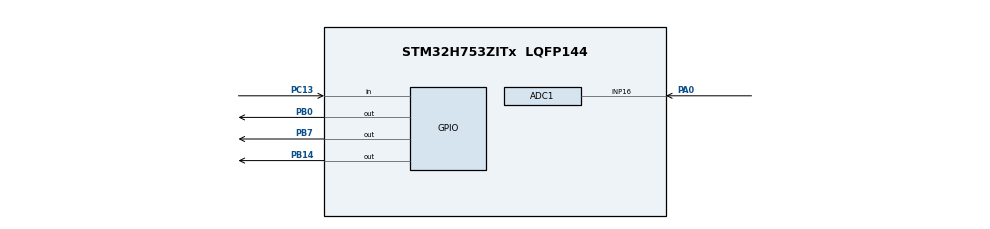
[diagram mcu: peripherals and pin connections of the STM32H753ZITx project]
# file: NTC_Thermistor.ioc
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ADC1.Channel-0\#ChannelRegularConversion=ADC_CHANNEL_16
ADC1.NbrOfConversionFlag=1
ADC1.OffsetNumber-0\#ChannelRegularConversion=ADC_OFFSET_NONE
ADC1.OffsetSignedSaturation-0\#ChannelRegularConversion=DISABLE
ADC1.Rank-0\#ChannelRegularConversion=1
ADC1.SamplingTime-0\#ChannelRegularConversion=ADC_SAMPLETIME_810CYCLES_5
ADC1.master=1
CORTEX_M7.CPU_DCache=Disabled
CORTEX_M7.CPU_ICache=Disabled
CORTEX_M7.MPU_Control=__NULL
CORTEX_M7.default_mode_Activation=1
Mcu.Family=STM32H7
Mcu.Name=STM32H753ZITx
Mcu.Package=LQFP144
NUCLEO-H753ZI.BUTTON=1
NUCLEO-H753ZI.LD1=true
NUCLEO-H753ZI.LD2=true
NUCLEO-H753ZI.LD3=true
NUCLEO-H753ZI.VCP=true
NVIC.EXTI15_10_IRQn=true\:0\:0\:false\:false\:true\:false\:true\:true
NVIC.PriorityGroup=NVIC_PRIORITYGROUP_4
PA0.Mode=IN16-Single-Ended
PA0.Signal=ADC1_INP16
PB0.Signal=GPIO_Output
PB14.Signal=GPIO_Output
PB7.Signal=GPIO_Output
PC13.Signal=GPIO_Input
PC14-OSC32_IN\ (OSC32_IN).Signal=RCC_OSC32_IN
PC15-OSC32_OUT\ (OSC32_OUT).Signal=RCC_OSC32_OUT
PD8.Signal=USART3_TX
PD9.Signal=USART3_RX
PH0-OSC_IN\ (PH0).Signal=RCC_OSC_IN
PH1-OSC_OUT\ (PH1).Signal=RCC_OSC_OUT
ProjectManager.HeapSize=0x200
ProjectManager.StackSize=0x400
ProjectManager.TargetToolchain=STM32CubeIDE
RCC.ADCFreq_Value=129000000
RCC.APB1Freq_Value=64000000
RCC.APB2Freq_Value=64000000
RCC.APB3Freq_Value=64000000
RCC.APB4Freq_Value=64000000
RCC.CortexFreq_Value=64000000
RCC.DIVM1=1
RCC.DIVN1=24
RCC.DIVQ1=4
RCC.HCLKFreq_Value=64000000
RCC.HSE_VALUE=8000000
RCC.PLLFRACN=0
RCC.PWR_Regulator_Voltage_Scale=PWR_REGULATOR_VOLTAGE_SCALE2
RCC.SYSCLKFreq_VALUE=64000000
RCC.USBFreq_Value=384000000
VP_MEMORYMAP_VS_MEMORYMAP.Mode=CurAppReg
VP_NUCLEO-H753ZI_VS_BSP_COMMON.Mode=COMMON
board=NUCLEO-H753ZI

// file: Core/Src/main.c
/* USER CODE BEGIN Header */
/**
  ******************************************************************************
  * @file           : main.c
  * @brief          : Main program body
  ******************************************************************************
  * @attention
  *
  * Copyright (c) 2025 STMicroelectronics.
  * All rights reserved.
  *
  * This software is licensed under terms that can be found in the LICENSE file
  * in the root directory of this software component.
  * If no LICENSE file comes with this software, it is provided AS-IS.
  *
  ******************************************************************************
  */
/* USER CODE END Header */
#include "main.h"

/* USER CODE BEGIN Includes */
#include "thermistor.h"
#include <stdio.h>
/* USER CODE END Includes */

COM_InitTypeDef BspCOMInit;
ADC_HandleTypeDef hadc1;

void SystemClock_Config(void);
static void MX_GPIO_Init(void);
static void MX_ADC1_Init(void);

int main(void)
{

  /* MCU Configuration--------------------------------------------------------*/

  /* Reset of all peripherals, Initializes the Flash interface and the Systick. */
  HAL_Init();

  /* Configure the system clock */
  SystemClock_Config();

  /* Initialize all configured peripherals */
  MX_GPIO_Init();
  MX_ADC1_Init();

  /* Initialize leds */
  BSP_LED_Init(LED_GREEN);
  BSP_LED_Init(LED_BLUE);
  BSP_LED_Init(LED_RED);

  /* Initialize USER push-button, will be used to trigger an interrupt each time it's pressed.*/
  BSP_PB_Init(BUTTON_USER, BUTTON_MODE_EXTI);

  /* Initialize COM1 port (115200, 8 bits (7-bit data + 1 stop bit), no parity */
  BspCOMInit.BaudRate   = 115200;
  BspCOMInit.WordLength = COM_WORDLENGTH_8B;
  BspCOMInit.StopBits   = COM_STOPBITS_1;
  BspCOMInit.Parity     = COM_PARITY_NONE;
  BspCOMInit.HwFlowCtl  = COM_HWCONTROL_NONE;
  if (BSP_COM_Init(COM1, &BspCOMInit) != BSP_ERROR_NONE)
  {
    Error_Handler();
  }

  /* Infinite loop */
  /* USER CODE BEGIN WHILE */
  while (1)
  {
	printf("Reading from thermistor!... \r\n");
	HAL_Delay(500); /* Insert delay 500 ms */

	// gets the temperature from thermistor
	float tempC = readThermistor();
	printf("Temperature (C): %.2f °C\r\n\r\n", tempC); // add linker flag "-u _printf_float to print this"
	HAL_Delay(500); /* Insert delay 500 ms */
    /* USER CODE END WHILE */

  }
}

void SystemClock_Config(void)
{
  RCC_OscInitTypeDef RCC_OscInitStruct = {0};
  RCC_ClkInitTypeDef RCC_ClkInitStruct = {0};

  /** Supply configuration update enable
  */
  HAL_PWREx_ConfigSupply(PWR_LDO_SUPPLY);

  /** Configure the main internal regulator output voltage
  */
  __HAL_PWR_VOLTAGESCALING_CONFIG(PWR_REGULATOR_VOLTAGE_SCALE2);

  while(!__HAL_PWR_GET_FLAG(PWR_FLAG_VOSRDY)) {}

  /** Macro to configure the PLL clock source
  */
  __HAL_RCC_PLL_PLLSOURCE_CONFIG(RCC_PLLSOURCE_HSI);

  /** Initializes the RCC Oscillators according to the specified parameters
  * in the RCC_OscInitTypeDef structure.
  */
  RCC_OscInitStruct.OscillatorType = RCC_OSCILLATORTYPE_HSI;
  RCC_OscInitStruct.HSIState = RCC_HSI_DIV1;
  RCC_OscInitStruct.HSICalibrationValue = RCC_HSICALIBRATION_DEFAULT;
  RCC_OscInitStruct.PLL.PLLState = RCC_PLL_NONE;
  if (HAL_RCC_OscConfig(&RCC_OscInitStruct) != HAL_OK)
  {
    Error_Handler();
  }

  /** Initializes the CPU, AHB and APB buses clocks
  */
  RCC_ClkInitStruct.ClockType = RCC_CLOCKTYPE_HCLK|RCC_CLOCKTYPE_SYSCLK
                              |RCC_CLOCKTYPE_PCLK1|RCC_CLOCKTYPE_PCLK2
                              |RCC_CLOCKTYPE_D3PCLK1|RCC_CLOCKTYPE_D1PCLK1;
  RCC_ClkInitStruct.SYSCLKSource = RCC_SYSCLKSOURCE_HSI;
  RCC_ClkInitStruct.SYSCLKDivider = RCC_SYSCLK_DIV1;
  RCC_ClkInitStruct.AHBCLKDivider = RCC_HCLK_DIV1;
  RCC_ClkInitStruct.APB3CLKDivider = RCC_APB3_DIV1;
  RCC_ClkInitStruct.APB1CLKDivider = RCC_APB1_DIV1;
  RCC_ClkInitStruct.APB2CLKDivider = RCC_APB2_DIV1;
  RCC_ClkInitStruct.APB4CLKDivider = RCC_APB4_DIV1;

  if (HAL_RCC_ClockConfig(&RCC_ClkInitStruct, FLASH_LATENCY_1) != HAL_OK)
  {
    Error_Handler();
  }
}

static void MX_ADC1_Init(void)
{

  ADC_MultiModeTypeDef multimode = {0};
  ADC_ChannelConfTypeDef sConfig = {0};

  /** Common config
  */
  hadc1.Instance = ADC1;
  hadc1.Init.ClockPrescaler = ADC_CLOCK_ASYNC_DIV4;
  hadc1.Init.Resolution = ADC_RESOLUTION_16B;
  hadc1.Init.ScanConvMode = ADC_SCAN_DISABLE;
  hadc1.Init.EOCSelection = ADC_EOC_SINGLE_CONV;
  hadc1.Init.LowPowerAutoWait = DISABLE;
  hadc1.Init.ContinuousConvMode = DISABLE;
  hadc1.Init.NbrOfConversion = 1;
  hadc1.Init.DiscontinuousConvMode = DISABLE;
  hadc1.Init.ExternalTrigConv = ADC_SOFTWARE_START;
  hadc1.Init.ExternalTrigConvEdge = ADC_EXTERNALTRIGCONVEDGE_NONE;
  hadc1.Init.ConversionDataManagement = ADC_CONVERSIONDATA_DR;
  hadc1.Init.Overrun = ADC_OVR_DATA_PRESERVED;
  hadc1.Init.LeftBitShift = ADC_LEFTBITSHIFT_NONE;
  hadc1.Init.OversamplingMode = DISABLE;
  hadc1.Init.Oversampling.Ratio = 1;
  if (HAL_ADC_Init(&hadc1) != HAL_OK)
  {
    Error_Handler();
  }

  /** Configure the ADC multi-mode
  */
  multimode.Mode = ADC_MODE_INDEPENDENT;
  if (HAL_ADCEx_MultiModeConfigChannel(&hadc1, &multimode) != HAL_OK)
  {
    Error_Handler();
  }

  /** Configure Regular Channel
  */
  sConfig.Channel = ADC_CHANNEL_16;
  sConfig.Rank = ADC_REGULAR_RANK_1;
  sConfig.SamplingTime = ADC_SAMPLETIME_810CYCLES_5;
  sConfig.SingleDiff = ADC_SINGLE_ENDED;
  sConfig.OffsetNumber = ADC_OFFSET_NONE;
  sConfig.Offset = 0;
  sConfig.OffsetSignedSaturation = DISABLE;
  if (HAL_ADC_ConfigChannel(&hadc1, &sConfig) != HAL_OK)
  {
    Error_Handler();
  }

}

static void MX_GPIO_Init(void)
{

  /* GPIO Ports Clock Enable */
  __HAL_RCC_GPIOC_CLK_ENABLE();
  __HAL_RCC_GPIOH_CLK_ENABLE();
  __HAL_RCC_GPIOA_CLK_ENABLE();

}

void Error_Handler(void)
{
  __disable_irq();
  while (1)
  {
  }
}
